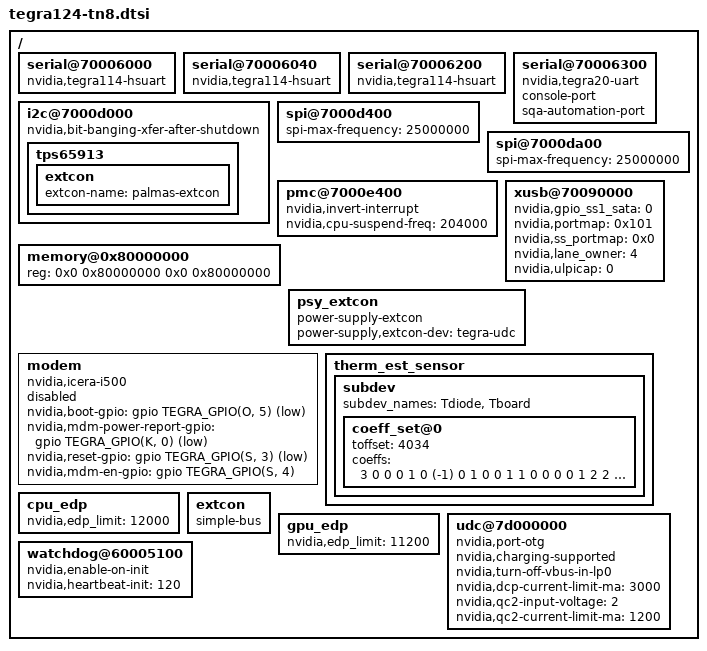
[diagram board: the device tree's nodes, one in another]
#include "tegra124-soc-shield.dtsi"

/ {
	serial@70006000 {
		compatible = "nvidia,tegra114-hsuart";
		status = "okay";
	};

	serial@70006040 {
		compatible = "nvidia,tegra114-hsuart";
		status = "okay";
	};

	serial@70006200 {
		compatible = "nvidia,tegra114-hsuart";
		status = "okay";
	};

	serial@70006300 {
		compatible = "nvidia,tegra20-uart", "nvidia,tegra114-hsuart";
		console-port;
		sqa-automation-port;
		status = "okay";
	};

	i2c@7000d000 {
		nvidia,bit-banging-xfer-after-shutdown;

		tps65913 {
			extcon {
				extcon-name = "palmas-extcon";
			};
		};
	};

	spi@7000d400 {
		status = "okay";
		spi-max-frequency = <25000000>;
	};

	spi@7000da00 {
		status = "okay";
		spi-max-frequency = <25000000>;
	};

	pmc@7000e400 {
		status = "okay";
		nvidia,invert-interrupt;
		nvidia,cpu-suspend-freq = <204000>;
	};

	xusb@70090000 {
		/* nvidia,uses_external_pmic;
		nvidia,gpio_controls_muxed_ss_lanes; */
		nvidia,gpio_ss1_sata = <0>;
		nvidia,portmap = <0x101>; /* SSP0, USB2P0 */
		nvidia,ss_portmap = <0x0>; /* SSP0 on USB2P0 */
		nvidia,lane_owner = <4>; /* USB3P0 */
		nvidia,ulpicap = <0>; /* No ulpi support. can we remove */
		status = "okay";
	};

	memory@0x80000000 {
		device_type = "memory";
		reg = <0x0 0x80000000 0x0 0x80000000>;
	};

	psy_extcon {
		compatible = "power-supply-extcon";
		power-supply,extcon-dev = "tegra-udc";
	};

	modem {
		compatible = "nvidia,icera-i500";
		nvidia,boot-gpio = <&gpio TEGRA_GPIO(O, 5) GPIO_ACTIVE_LOW>;
		nvidia,mdm-power-report-gpio = <&gpio TEGRA_GPIO(K, 0) GPIO_ACTIVE_LOW>;
		nvidia,reset-gpio = <&gpio TEGRA_GPIO(S, 3) GPIO_ACTIVE_LOW>;
		nvidia,mdm-en-gpio = <&gpio TEGRA_GPIO(S, 4) GPIO_ACTIVE_HIGH>;
		status = "disabled";
	};

	therm_est_sensor {
		subdev {
			subdev_names = "Tdiode", "Tboard";

			coeff_set@0 {
				toffset = <4034>;
				coeffs = <
					3 0 0 0 1 0 (-1) 0 1 0 0 1 1 0 0 0 0 1 2 2
					1 1 2 8 6 (-8) (-13) (-9) (-9) (-8) (-17) (-18) (-18) (-16) 2 17 15 27 42 60
				>;
			};
		};
	};

	cpu_edp {
		nvidia,edp_limit = <12000>;
	};

	extcon {
		compatible = "simple-bus";
		device_type = "external-connection";
		#address-cells = <1>;
		#size-cells = <0>;
	};

	gpu_edp {
		nvidia,edp_limit = <11200>;
	};

	udc@7d000000 {
		nvidia,port-otg;
		nvidia,charging-supported;
		nvidia,turn-off-vbus-in-lp0;
		nvidia,dcp-current-limit-ma = <3000>;
		nvidia,qc2-input-voltage = <2>;
		nvidia,qc2-current-limit-ma = <1200>;
	};

	watchdog@60005100 {
		nvidia,enable-on-init;
		nvidia,heartbeat-init = <120>;
	};
};
